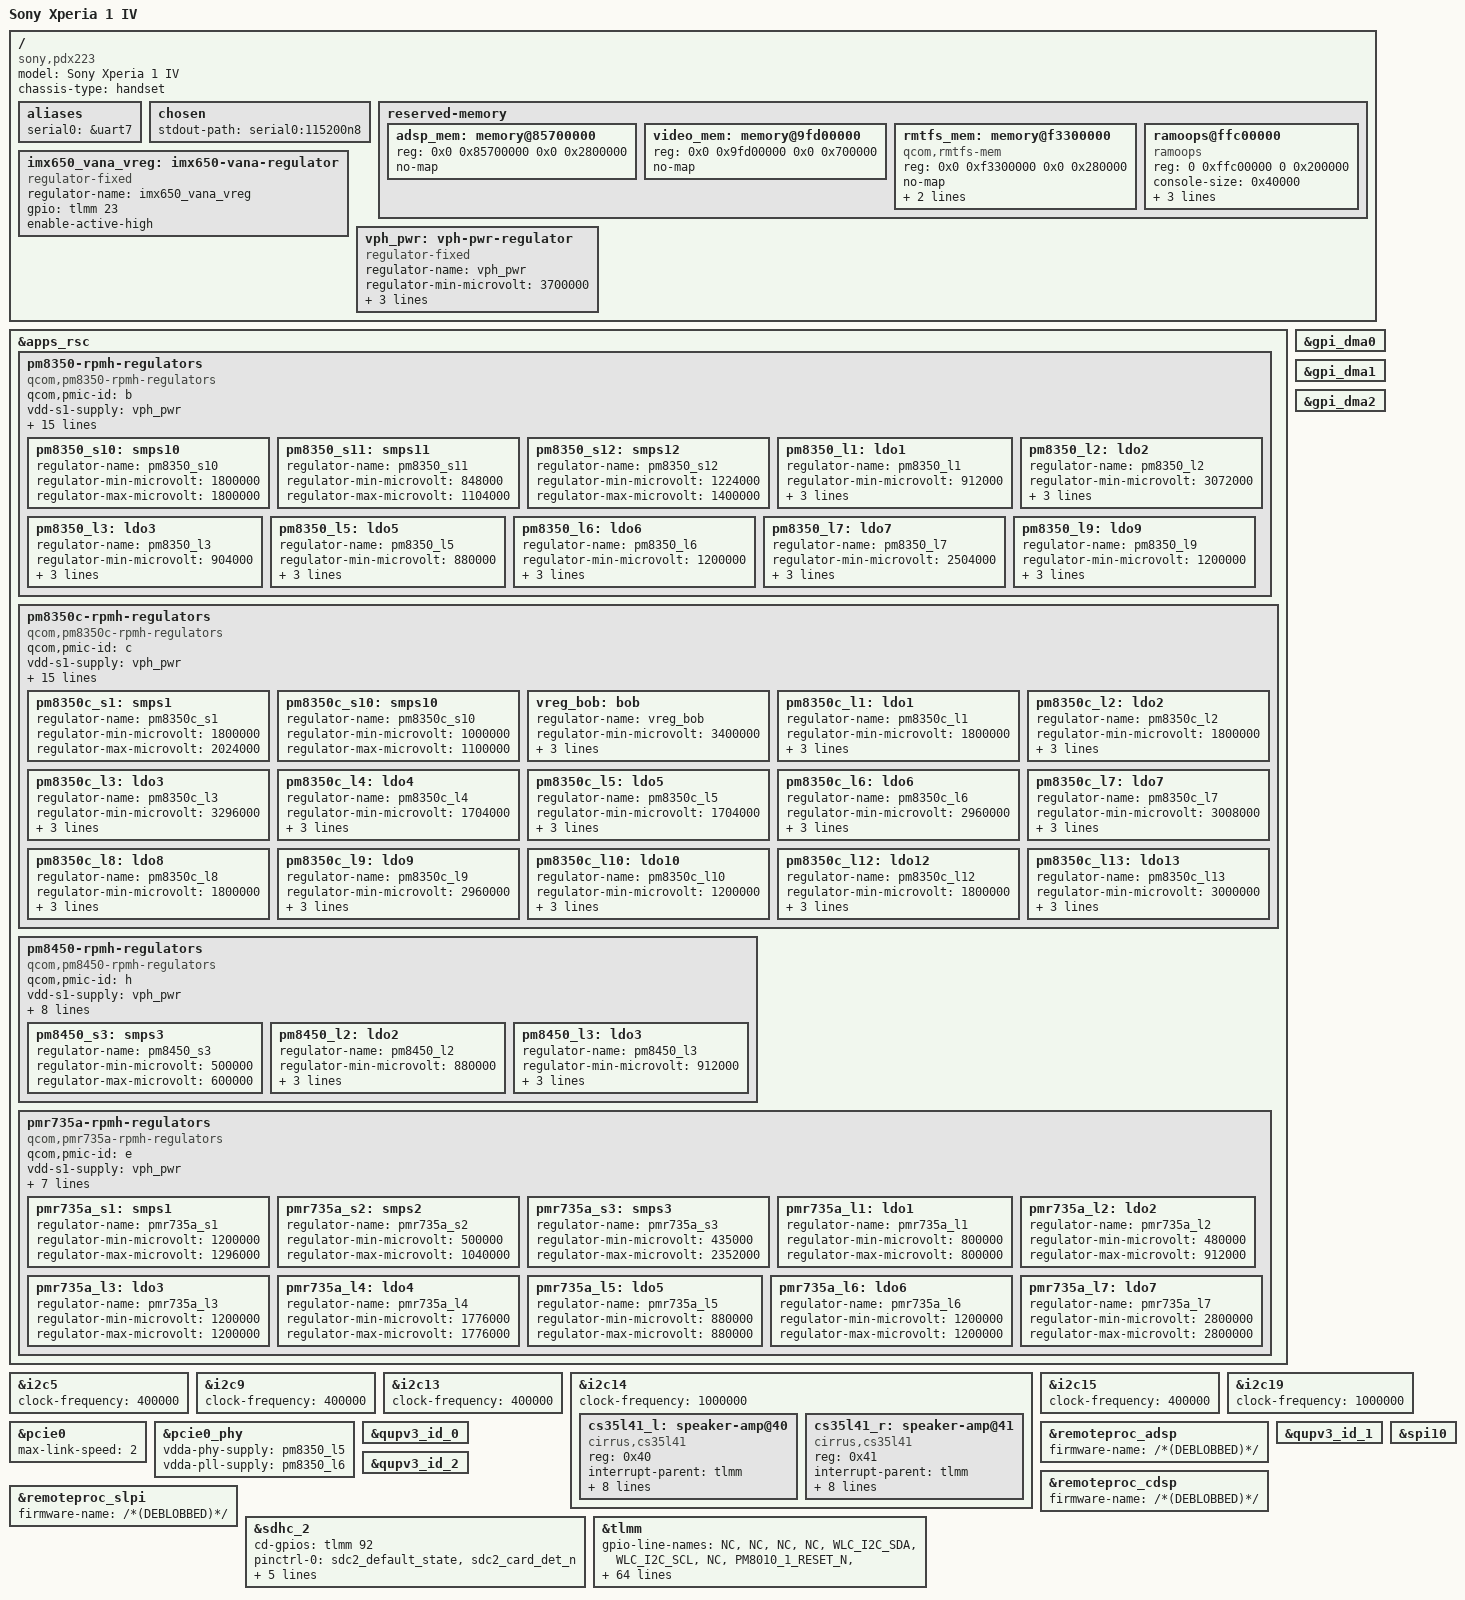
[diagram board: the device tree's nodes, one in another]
// SPDX-License-Identifier: BSD-3-Clause
/*
 * Copyright (c) 2022, Konrad Dybcio <konrad.dybcio@somainline.org>
 * Copyright (c) 2022, Linaro Limited
 */

/dts-v1/;

#include "sm8450-sony-xperia-nagara.dtsi"

/ {
	model = "Sony Xperia 1 IV";
	compatible = "sony,pdx223", "qcom,sm8450";
	chassis-type = "handset";

	aliases {
		serial0 = &uart7;
	};

	chosen {
		stdout-path = "serial0:115200n8";
	};

	reserved-memory {
		adsp_mem: memory@85700000 {
			reg = <0x0 0x85700000 0x0 0x2800000>;
			no-map;
		};

		video_mem: memory@9fd00000 {
			reg = <0x0 0x9fd00000 0x0 0x700000>;
			no-map;
		};

		rmtfs_mem: memory@f3300000 {
			compatible = "qcom,rmtfs-mem";
			reg = <0x0 0xf3300000 0x0 0x280000>;
			no-map;

			qcom,client-id = <1>;
			qcom,vmid = <15>;
		};

		ramoops@ffc00000 {
			compatible = "ramoops";
			reg = <0 0xffc00000 0 0x200000>;
			console-size = <0x40000>;
			record-size = <0x1000>;
			ecc-size = <16>;
			no-map;
		};
	};

	/* Sadly, the voltages for these GPIO regulators are unknown. */
	imx650_vana_vreg: imx650-vana-regulator {
		compatible = "regulator-fixed";
		regulator-name = "imx650_vana_vreg";
		gpio = <&tlmm 23 GPIO_ACTIVE_HIGH>;
		enable-active-high;
	};

	vph_pwr: vph-pwr-regulator {
		compatible = "regulator-fixed";
		regulator-name = "vph_pwr";
		regulator-min-microvolt = <3700000>;
		regulator-max-microvolt = <3700000>;

		regulator-always-on;
		regulator-boot-on;
	};
};

&apps_rsc {
	pm8350-rpmh-regulators {
		compatible = "qcom,pm8350-rpmh-regulators";
		qcom,pmic-id = "b";

		vdd-s1-supply = <&vph_pwr>;
		vdd-s2-supply = <&vph_pwr>;
		vdd-s3-supply = <&vph_pwr>;
		vdd-s4-supply = <&vph_pwr>;
		vdd-s5-supply = <&vph_pwr>;
		vdd-s6-supply = <&vph_pwr>;
		vdd-s7-supply = <&vph_pwr>;
		vdd-s8-supply = <&vph_pwr>;
		vdd-s9-supply = <&vph_pwr>;
		vdd-s10-supply = <&vph_pwr>;
		vdd-s11-supply = <&vph_pwr>;
		vdd-s12-supply = <&vph_pwr>;

		vdd-l1-l4-supply = <&pm8350_s11>;
		vdd-l2-l7-supply = <&vreg_bob>;
		vdd-l3-l5-supply = <&vreg_bob>;
		vdd-l6-l9-l10-supply = <&pm8350_s12>;

		/*
		 * ARC regulators:
		 * s5 - gfx.lvl
		 * l8 - lcx.lvl
		 */

		pm8350_s10: smps10 {
			regulator-name = "pm8350_s10";
			regulator-min-microvolt = <1800000>;
			regulator-max-microvolt = <1800000>;
		};

		pm8350_s11: smps11 {
			regulator-name = "pm8350_s11";
			regulator-min-microvolt = <848000>;
			regulator-max-microvolt = <1104000>;
		};

		pm8350_s12: smps12 {
			regulator-name = "pm8350_s12";
			regulator-min-microvolt = <1224000>;
			regulator-max-microvolt = <1400000>;
		};

		pm8350_l1: ldo1 {
			regulator-name = "pm8350_l1";
			regulator-min-microvolt = <912000>;
			regulator-max-microvolt = <920000>;
			regulator-initial-mode = <RPMH_REGULATOR_MODE_HPM>;
		};

		pm8350_l2: ldo2 {
			regulator-name = "pm8350_l2";
			regulator-min-microvolt = <3072000>;
			regulator-max-microvolt = <3072000>;
			regulator-initial-mode = <RPMH_REGULATOR_MODE_HPM>;
		};

		pm8350_l3: ldo3 {
			regulator-name = "pm8350_l3";
			regulator-min-microvolt = <904000>;
			regulator-max-microvolt = <904000>;
			regulator-initial-mode = <RPMH_REGULATOR_MODE_HPM>;
		};

		pm8350_l5: ldo5 {
			regulator-name = "pm8350_l5";
			regulator-min-microvolt = <880000>;
			regulator-max-microvolt = <912000>;
			regulator-initial-mode = <RPMH_REGULATOR_MODE_HPM>;
		};

		pm8350_l6: ldo6 {
			regulator-name = "pm8350_l6";
			regulator-min-microvolt = <1200000>;
			regulator-max-microvolt = <1200000>;
			regulator-initial-mode = <RPMH_REGULATOR_MODE_HPM>;
		};

		pm8350_l7: ldo7 {
			regulator-name = "pm8350_l7";
			regulator-min-microvolt = <2504000>;
			regulator-max-microvolt = <2504000>;
			regulator-initial-mode = <RPMH_REGULATOR_MODE_HPM>;
		};

		pm8350_l9: ldo9 {
			regulator-name = "pm8350_l9";
			regulator-min-microvolt = <1200000>;
			regulator-max-microvolt = <1200000>;
			regulator-initial-mode = <RPMH_REGULATOR_MODE_HPM>;
		};
	};

	pm8350c-rpmh-regulators {
		compatible = "qcom,pm8350c-rpmh-regulators";
		qcom,pmic-id = "c";

		vdd-s1-supply = <&vph_pwr>;
		vdd-s2-supply = <&vph_pwr>;
		vdd-s3-supply = <&vph_pwr>;
		vdd-s4-supply = <&vph_pwr>;
		vdd-s5-supply = <&vph_pwr>;
		vdd-s6-supply = <&vph_pwr>;
		vdd-s7-supply = <&vph_pwr>;
		vdd-s8-supply = <&vph_pwr>;
		vdd-s9-supply = <&vph_pwr>;
		vdd-s10-supply = <&vph_pwr>;

		vdd-l1-l12-supply = <&vreg_bob>;
		vdd-l2-l8-supply = <&vreg_bob>;
		vdd-l3-l4-l5-l7-l13-supply = <&vreg_bob>;
		vdd-l6-l9-l11-supply = <&vreg_bob>;
		vdd-l10-supply = <&pm8350_s12>;

		vdd-bob-supply = <&vph_pwr>;

		/*
		 * ARC regulators:
		 * s2 - mxc.lvl
		 * s4 - mss.lvl
		 * s6 - cx.lvl
		 */

		pm8350c_s1: smps1 {
			regulator-name = "pm8350c_s1";
			regulator-min-microvolt = <1800000>;
			regulator-max-microvolt = <2024000>;
		};

		pm8350c_s10: smps10 {
			regulator-name = "pm8350c_s10";
			regulator-min-microvolt = <1000000>;
			regulator-max-microvolt = <1100000>;
		};

		vreg_bob: bob {
			regulator-name = "vreg_bob";
			regulator-min-microvolt = <3400000>;
			regulator-max-microvolt = <3960000>;
			regulator-initial-mode = <RPMH_REGULATOR_MODE_AUTO>;
		};

		pm8350c_l1: ldo1 {
			regulator-name = "pm8350c_l1";
			regulator-min-microvolt = <1800000>;
			regulator-max-microvolt = <1800000>;
			regulator-initial-mode = <RPMH_REGULATOR_MODE_HPM>;
		};

		pm8350c_l2: ldo2 {
			regulator-name = "pm8350c_l2";
			regulator-min-microvolt = <1800000>;
			regulator-max-microvolt = <1800000>;
			regulator-initial-mode = <RPMH_REGULATOR_MODE_HPM>;
		};

		pm8350c_l3: ldo3 {
			regulator-name = "pm8350c_l3";
			regulator-min-microvolt = <3296000>;
			regulator-max-microvolt = <3304000>;
			regulator-initial-mode = <RPMH_REGULATOR_MODE_HPM>;
		};

		pm8350c_l4: ldo4 {
			regulator-name = "pm8350c_l4";
			regulator-min-microvolt = <1704000>;
			regulator-max-microvolt = <3000000>;
			regulator-initial-mode = <RPMH_REGULATOR_MODE_HPM>;
		};

		pm8350c_l5: ldo5 {
			regulator-name = "pm8350c_l5";
			regulator-min-microvolt = <1704000>;
			regulator-max-microvolt = <3000000>;
			regulator-initial-mode = <RPMH_REGULATOR_MODE_HPM>;
		};

		pm8350c_l6: ldo6 {
			regulator-name = "pm8350c_l6";
			regulator-min-microvolt = <2960000>;
			/* Originally max = 3008000 but SDHCI expects 2960000 */
			regulator-max-microvolt = <2960000>;
			regulator-initial-mode = <RPMH_REGULATOR_MODE_HPM>;
		};

		pm8350c_l7: ldo7 {
			regulator-name = "pm8350c_l7";
			regulator-min-microvolt = <3008000>;
			regulator-max-microvolt = <3008000>;
			regulator-initial-mode = <RPMH_REGULATOR_MODE_HPM>;
		};

		pm8350c_l8: ldo8 {
			regulator-name = "pm8350c_l8";
			regulator-min-microvolt = <1800000>;
			regulator-max-microvolt = <1800000>;
			regulator-initial-mode = <RPMH_REGULATOR_MODE_HPM>;
		};

		pm8350c_l9: ldo9 {
			regulator-name = "pm8350c_l9";
			regulator-min-microvolt = <2960000>;
			/* Originally max = 3008000 but SDHCI expects 2960000 */
			regulator-max-microvolt = <2960000>;
			regulator-initial-mode = <RPMH_REGULATOR_MODE_HPM>;
		};

		pm8350c_l10: ldo10 {
			regulator-name = "pm8350c_l10";
			regulator-min-microvolt = <1200000>;
			regulator-max-microvolt = <1200000>;
			regulator-initial-mode = <RPMH_REGULATOR_MODE_HPM>;
		};

		pm8350c_l12: ldo12 {
			regulator-name = "pm8350c_l12";
			regulator-min-microvolt = <1800000>;
			regulator-max-microvolt = <1968000>;
			regulator-initial-mode = <RPMH_REGULATOR_MODE_HPM>;
		};

		pm8350c_l13: ldo13 {
			regulator-name = "pm8350c_l13";
			regulator-min-microvolt = <3000000>;
			regulator-max-microvolt = <3000000>;
			regulator-initial-mode = <RPMH_REGULATOR_MODE_HPM>;
		};
	};

	pm8450-rpmh-regulators {
		compatible = "qcom,pm8450-rpmh-regulators";
		qcom,pmic-id = "h";

		vdd-s1-supply = <&vph_pwr>;
		vdd-s2-supply = <&vph_pwr>;
		vdd-s3-supply = <&vph_pwr>;
		vdd-s4-supply = <&vph_pwr>;
		vdd-s5-supply = <&vph_pwr>;
		vdd-s6-supply = <&vph_pwr>;

		vdd-l2-supply = <&vreg_bob>;
		vdd-l3-supply = <&vreg_bob>;
		vdd-l4-supply = <&vreg_bob>;

		/*
		 * ARC regulators:
		 * S2 - ebi.lvl
		 * S4 - mmcx.lvl
		 * S6 - mx.lvl
		 * L1 - lmx.lvl
		 */

		pm8450_s3: smps3 {
			regulator-name = "pm8450_s3";
			regulator-min-microvolt = <500000>;
			regulator-max-microvolt = <600000>;
		};

		pm8450_l2: ldo2 {
			regulator-name = "pm8450_l2";
			regulator-min-microvolt = <880000>;
			regulator-max-microvolt = <912000>;
			regulator-initial-mode = <RPMH_REGULATOR_MODE_HPM>;
		};

		pm8450_l3: ldo3 {
			regulator-name = "pm8450_l3";
			regulator-min-microvolt = <912000>;
			regulator-max-microvolt = <912000>;
			regulator-initial-mode = <RPMH_REGULATOR_MODE_HPM>;
		};
	};

	pmr735a-rpmh-regulators {
		compatible = "qcom,pmr735a-rpmh-regulators";
		qcom,pmic-id = "e";

		vdd-s1-supply = <&vph_pwr>;
		vdd-s2-supply = <&vph_pwr>;
		vdd-s3-supply = <&vph_pwr>;

		vdd-l1-l2-supply = <&pmr735a_s2>;
		vdd-l3-supply = <&pmr735a_s1>;
		vdd-l4-supply = <&pm8350c_s1>;
		vdd-l5-l6-supply = <&pm8350c_s1>;
		vdd-l7-bob-supply = <&vreg_bob>;

		pmr735a_s1: smps1 {
			regulator-name = "pmr735a_s1";
			regulator-min-microvolt = <1200000>;
			regulator-max-microvolt = <1296000>;
		};

		pmr735a_s2: smps2 {
			regulator-name = "pmr735a_s2";
			regulator-min-microvolt = <500000>;
			regulator-max-microvolt = <1040000>;
		};

		pmr735a_s3: smps3 {
			regulator-name = "pmr735a_s3";
			regulator-min-microvolt = <435000>;
			regulator-max-microvolt = <2352000>;
		};

		pmr735a_l1: ldo1 {
			regulator-name = "pmr735a_l1";
			regulator-min-microvolt = <800000>;
			regulator-max-microvolt = <800000>;
		};

		pmr735a_l2: ldo2 {
			regulator-name = "pmr735a_l2";
			regulator-min-microvolt = <480000>;
			regulator-max-microvolt = <912000>;
		};

		pmr735a_l3: ldo3 {
			regulator-name = "pmr735a_l3";
			regulator-min-microvolt = <1200000>;
			regulator-max-microvolt = <1200000>;
		};

		pmr735a_l4: ldo4 {
			regulator-name = "pmr735a_l4";
			regulator-min-microvolt = <1776000>;
			regulator-max-microvolt = <1776000>;
		};

		pmr735a_l5: ldo5 {
			regulator-name = "pmr735a_l5";
			regulator-min-microvolt = <880000>;
			regulator-max-microvolt = <880000>;
		};

		pmr735a_l6: ldo6 {
			regulator-name = "pmr735a_l6";
			regulator-min-microvolt = <1200000>;
			regulator-max-microvolt = <1200000>;
		};

		pmr735a_l7: ldo7 {
			regulator-name = "pmr735a_l7";
			regulator-min-microvolt = <2800000>;
			regulator-max-microvolt = <2800000>;
		};
	};
};

&gpi_dma0 {
	status = "okay";
};

&gpi_dma1 {
	status = "okay";
};

&gpi_dma2 {
	status = "okay";
};

/* I2C4 is used, it hosts a Samsung touchscreen, but GPI DMA is broken.. */

&i2c5 {
	clock-frequency = <400000>;
	status = "okay";

	/* Dialog SLG51000 CMIC @ 75 */
};

&i2c9 {
	clock-frequency = <400000>;
	status = "okay";

	/* NXP SN1X0 NFC @ 28 */
};

&i2c13 {
	clock-frequency = <400000>;
	status = "okay";

	/* Richwave RTC6226 FM Radio Receiver @ 64 */
};

&i2c14 {
	clock-frequency = <1000000>;
	status = "okay";

	cs35l41_l: speaker-amp@40 {
		compatible = "cirrus,cs35l41";
		reg = <0x40>;
		interrupt-parent = <&tlmm>;
		interrupts = <182 IRQ_TYPE_LEVEL_LOW>;
		reset-gpios = <&tlmm 183 GPIO_ACTIVE_HIGH>;
		cirrus,boost-peak-milliamp = <4000>;
		cirrus,boost-ind-nanohenry = <1000>;
		cirrus,boost-cap-microfarad = <15>;
		cirrus,gpio2-src-select = <2>;
		cirrus,gpio2-output-enable;
		cirrus,asp-sdout-hiz = <3>;
		#sound-dai-cells = <1>;
	};

	cs35l41_r: speaker-amp@41 {
		compatible = "cirrus,cs35l41";
		reg = <0x41>;
		interrupt-parent = <&tlmm>;
		interrupts = <182 IRQ_TYPE_LEVEL_LOW>;
		reset-gpios = <&tlmm 183 GPIO_ACTIVE_HIGH>;
		cirrus,boost-peak-milliamp = <4000>;
		cirrus,boost-ind-nanohenry = <1000>;
		cirrus,boost-cap-microfarad = <15>;
		cirrus,gpio2-src-select = <2>;
		cirrus,gpio2-output-enable;
		cirrus,asp-sdout-hiz = <3>;
		#sound-dai-cells = <1>;
	};
};

&i2c15 {
	clock-frequency = <400000>;
	status = "okay";

	/* AMS TCS3490 RGB+IR color sensor @ 72 */
};

&i2c19 {
	clock-frequency = <1000000>;
	status = "okay";

	/* Cirrus Logic CS40L25A boosted haptics driver @ 40 */
};

&pcie0 {
	max-link-speed = <2>;
	status = "okay";
};

&pcie0_phy {
	vdda-phy-supply = <&pm8350_l5>;
	vdda-pll-supply = <&pm8350_l6>;
	status = "okay";
};

&remoteproc_adsp {
	firmware-name = "/*(DEBLOBBED)*/";
	status = "okay";
};

&remoteproc_cdsp {
	firmware-name = "/*(DEBLOBBED)*/";
	status = "okay";
};

&remoteproc_slpi {
	firmware-name = "/*(DEBLOBBED)*/";
	status = "okay";
};

&qupv3_id_0 {
	status = "okay";
};

&qupv3_id_1 {
	status = "okay";
};

&qupv3_id_2 {
	status = "okay";
};

&sdhc_2 {
	cd-gpios = <&tlmm 92 GPIO_ACTIVE_HIGH>;
	pinctrl-names = "default", "sleep";
	pinctrl-0 = <&sdc2_default_state &sdc2_card_det_n>;
	pinctrl-1 = <&sdc2_sleep_state &sdc2_card_det_n>;
	vmmc-supply = <&pm8350c_l9>;
	vqmmc-supply = <&pm8350c_l6>;
	no-sdio;
	no-mmc;
	status = "okay";
};

&spi10 {
	status = "okay";

	/* NXP SN1X0 NFC Secure Element @ 0 */
};

&tlmm {
	gpio-line-names = "NC", /* GPIO_0 */
			  "NC",
			  "NC",
			  "NC",
			  "WLC_I2C_SDA",
			  "WLC_I2C_SCL",
			  "NC",
			  "PM8010_1_RESET_N",
			  "WLC_INT_N",
			  "NC",
			  "NC", /* GPIO_10 */
			  "PM8010_2_RESET_N",
			  "DISP_ERR_FG",
			  "HALL_INT_N",
			  "ALS_PROX_INT_N",
			  "IMU1_INT",
			  "TS_I2C_SDA",
			  "TS_I2C_SCL",
			  "DISP_RESET_N",
			  "DISP_VDDR_EN",
			  "TS_RESET_N", /* GPIO_20 */
			  "TS_INT_N",
			  "NC",
			  "TELEC_PWR_EN",
			  "CAM1_RESET_N",
			  "LEO_CAM0_RESET_N",
			  "DEBUG_UART_TX",
			  "DEBUG_UART_RX",
			  "FP_SPI_MISO",
			  "FP_SPI_MOSI",
			  "FP_SPI_CLK", /* GPIO_30 */
			  "FP_SPI_CS_N",
			  "NFC_I2C_SDA",
			  "NFC_I2C_SCL",
			  "NFC_EN",
			  "NFC_CLK_REQ",
			  "NFC_ESE_SPI_MISO",
			  "NFC_ESE_SPI_MOSI",
			  "NFC_ESE_SPI_CLK",
			  "NFC_ESE_SPI_CS",
			  "FP_INT_N", /* GPIO_40 */
			  "NC",
			  "FP_RESET_N",
			  "WCD_RST_N",
			  "NC",
			  "NFC_DWL_REQ",
			  "NFC_IRQ",
			  "FORCE_USB_BOOT",
			  "APPS_I2C_1_SDA",
			  "APPS_I2C_1_SCL",
			  "SBU_SW_OE", /* GPIO_50 */
			  "SBU_SW_SEL",
			  "SPK_AMP_I2C_SDA",
			  "SPK_AMP_I2C_SCL",
			  "NC",
			  "NC",
			  "CAMSENSOR_I2C_SDA",
			  "CAMSENSOR_I2C_SCL",
			  "GNSS_ELNA_EN0",
			  "NC",
			  "NC", /* GPIO_60 */
			  "NC",
			  "NC",
			  "NC",
			  "NC",
			  "NC",
			  "RGBC_IR_INT",
			  "NC",
			  "NC",
			  "NC",
			  "NC", /* GPIO_70 */
			  "NC",
			  "HAP_I2C_SDA",
			  "HAP_I2C_SCL",
			  "HAP_RST_N",
			  "HAP_INT_N",
			  "HST_BT_UART_CTS",
			  "HST_BT_UART_RFR",
			  "HST_BT_UART_TX",
			  "HST_BT_UART_RX",
			  "HST_WLAN_EN", /* GPIO_80 */
			  "HST_BT_EN",
			  "HST_SW_CTRL",
			  "NC",
			  "NC",
			  "NC",
			  "DISP_VSYNC",
			  "NC",
			  "NC",
			  "HW_ID_0",
			  "HW_ID_1", /* GPIO_90 */
			  "USB_CC_DIR",
			  "TRAY_DET",
			  "SW_SERVICE",
			  "PCIE0_RESET_N",
			  "PCIE0_CLK_REQ_N",
			  "PCIE0_WAKE_N",
			  "OIS_ENABLE_WIDE",
			  "DEBUG_GPIO0",
			  "NC",
			  "CAM_MCLK0", /* GPIO_100 */
			  "CAM_MCLK1",
			  "CAM_MCLK2",
			  "CAM_MCLK3",
			  "NC",
			  "NC",
			  "TOF_RST_N",
			  "CAM_SOF",
			  "NC",
			  "AFEXPTMG_TELE",
			  "CCI_I2C0_SDA", /* GPIO_110 */
			  "CCI_I2C0_SCL",
			  "CCI_I2C1_SDA",
			  "CCI_I2C1_SCL",
			  "CCI_I2C2_SDA",
			  "CCI_I2C2_SCL",
			  "NC",
			  "CAM2_RESET_N",
			  "NC",
			  "EXT_VD0_XVS",
			  "CAM3_RESET_N", /* GPIO_120 */
			  "NC",
			  "NC",
			  "NC",
			  "NC",
			  "RF_ID_EXTENSION_2",
			  "HAP_I2S_CLK",
			  "HAP_I2S_DOUT",
			  "HAP_TRG1",
			  "HAP_I2S_SYNC",
			  "UIM1_DATA", /* GPIO_130 */
			  "UIM1_CLK",
			  "UIM1_RESET",
			  "TRAY_DET",
			  "UIM2_DATA",
			  "UIM2_CLK",
			  "UIM2_RESET",
			  "UIM2_PRESENT",
			  "SM_RFFE0_CLK",
			  "SM_RFFE0_DATA",
			  "SM_RFFE1_CLK", /* GPIO_140 */
			  "SM_RFFE1_DATA",
			  "SM_MSS_GRFC4",
			  "HST_AS_EN",
			  "LAA_RX_EN",
			  "NC",
			  "SM_RFFE4_CLK",
			  "SM_RFFE4_DATA",
			  "WLAN_COEX_UART1_RX",
			  "WLAN_COEX_UART1_TX",
			  "RF_LCD_ID_EN", /* GPIO_150 */
			  "RF_ID_EXTENSION",
			  "SM_MSS_GRFC12",
			  "NFC_COLD_RST",
			  "NC",
			  "NC",
			  "SDR1_QLINK0_REQ",
			  "SDR1_QLINK0_EN",
			  "SDR1_QLINK0_WMSS_RESET_N",
			  "QLINK1_REQ",
			  "QLINK1_EN", /* GPIO_160 */
			  "QLINK1_WMSS_RESET_N",
			  "SDR2_QLINK2_REQ",
			  "SDR2_QLINK2_EN",
			  "SDR2_QLINK2_WMSS_RESET_N",
			  "WCD_SWR_TX_CLK",
			  "WCD_SWR_TX_DATA0",
			  "WCD_SWR_TX_DATA1",
			  "WCD_SWR_RX_CLK",
			  "WCD_SWR_RX_DATA0",
			  "WCD_SWR_RX_DATA1", /* GPIO_170 */
			  "SM_DMIC1_CLK",
			  "SM_DMIC1_DATA",
			  "SM_DMIC2_CLK",
			  "SM_DMIC2_DATA",
			  "SPK_AMP_I2S_CLK",
			  "SPK_AMP_I2S_WS",
			  "NC",
			  "NC",
			  "WCD_SWR_TX_DATA2",
			  "SPK_AMP_I2S_ASP_DIN", /* GPIO_180 */
			  "SPK_AMP_I2S_ASP_DOUT",
			  "SPK_AMP_INT_N",
			  "SPK_AMP_RESET_N",
			  "HST_BT_WLAN_SLIMBUS_CLK",
			  "HST_BT_WLAN_SLIMBUS_DAT0",
			  "NC",
			  "NC",
			  "NC",
			  "NC",
			  "MAG_I2C_SDA", /* GPIO_190 */
			  "MAG_I2C_SCL",
			  "IMU_SPI_MISO",
			  "IMU_SPI_MOSI",
			  "IMU_SPI_CLK",
			  "IMU_SPI_CS_N",
			  "SENSOR_I2C_SDA",
			  "SENSOR_I2C_SCL",
			  "OIS_TELE_I2C_SDA",
			  "OIS_TELE_I2C_SCL",
			  "NC", /* GPIO_200 */
			  "OIS_ENABLE_TELE",
			  "HST_BLE_UART_TX",
			  "HST_BLE_UART_RX",
			  "HSTP_CLK_CFG_SEL",
			  "NC",
			  "APPS_I2C_0_SDA",
			  "APPS_I2C_0_SCL",
			  "CCI_I2C3_SDA",
			  "CCI_I2C3_SCL";
};
